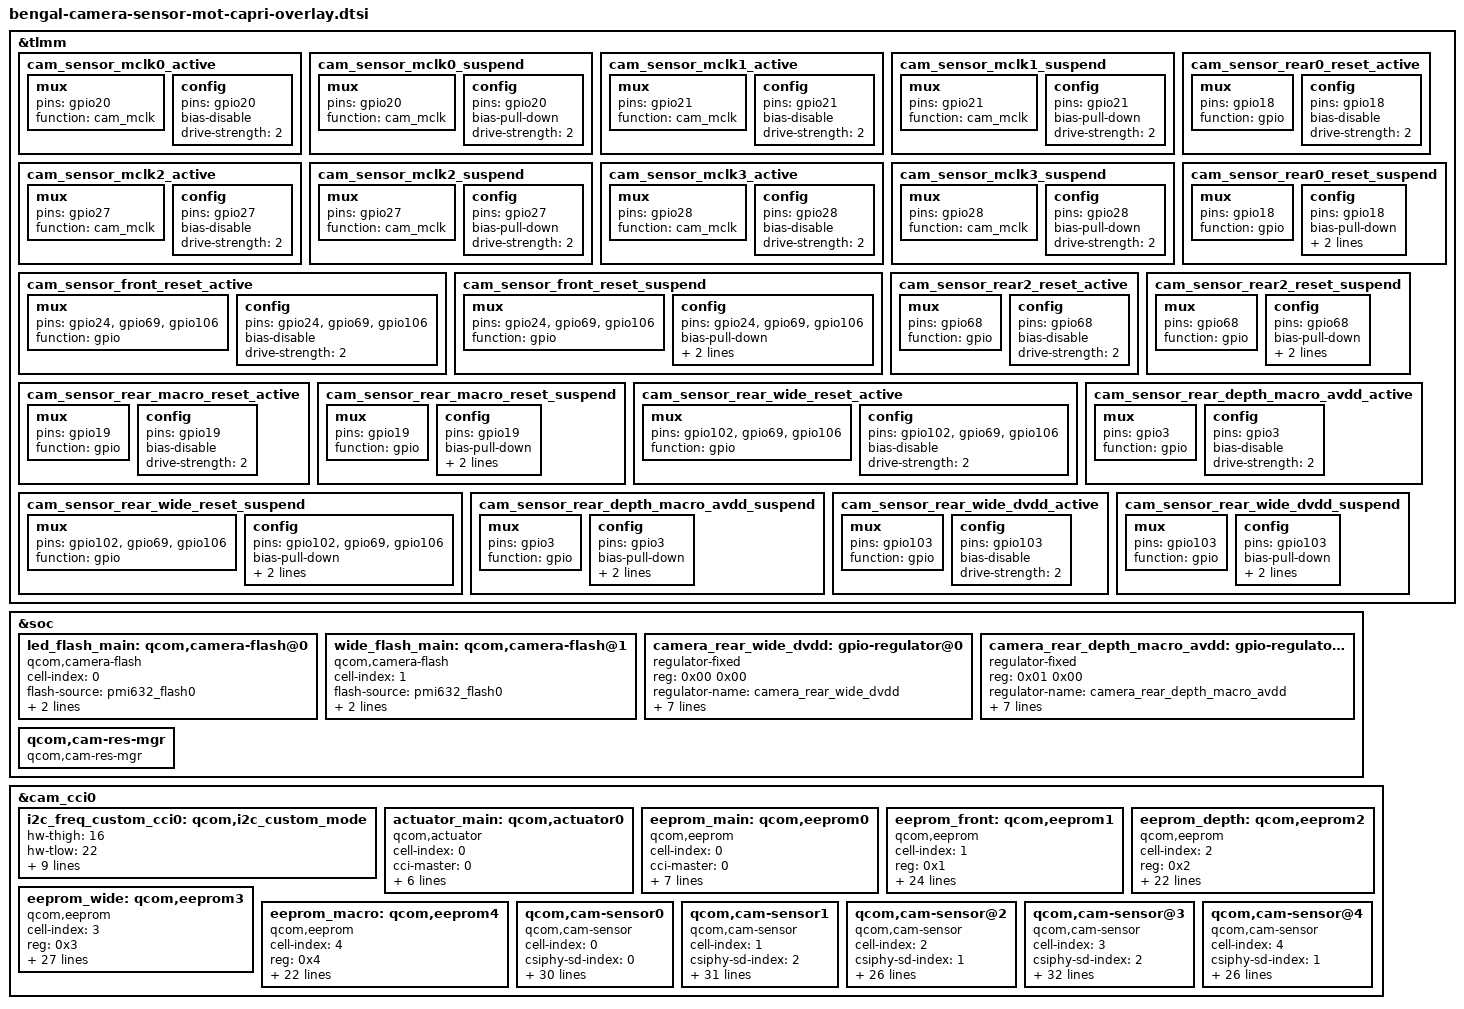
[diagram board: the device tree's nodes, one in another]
#include <dt-bindings/clock/qcom,gcc-bengal.h>


&tlmm {
	cam_sensor_mclk0_active: cam_sensor_mclk0_active {
		/* MCLK 0*/
		mux {
			pins = "gpio20";
			function = "cam_mclk";
		};

		config {
			pins = "gpio20";
			bias-disable;
			drive-strength = <2>;
		};
	};

	cam_sensor_mclk0_suspend: cam_sensor_mclk0_suspend {
		/* MCLK 0*/
		mux {
			pins = "gpio20";
			function = "cam_mclk";
		};

		config {
			pins = "gpio20";
			bias-pull-down;
			drive-strength = <2>;
		};
	};

	cam_sensor_mclk1_active: cam_sensor_mclk1_active {
		mux {
			pins = "gpio21";
			function = "cam_mclk";
		};

		config {
			pins = "gpio21";
			bias-disable; /* No PULL */
			drive-strength = <2>; /* 2 MA */
		};
	};

	cam_sensor_mclk1_suspend: cam_sensor_mclk1_suspend {
		mux {
			pins = "gpio21";
			function = "cam_mclk";
		};

		config {
			pins = "gpio21";
			bias-pull-down;
			drive-strength = <2>; /* 2 MA */
		};
	};

	cam_sensor_mclk2_active: cam_sensor_mclk2_active {
		mux {
			pins = "gpio27";
			function = "cam_mclk";
		};

		config {
			pins = "gpio27";
			bias-disable;
			drive-strength = <2>;
		};
	};

	cam_sensor_mclk2_suspend: cam_sensor_mclk2_suspend {
		mux {
			pins = "gpio27";
			function = "cam_mclk";
		};

		config {
			pins = "gpio27";
			bias-pull-down;
			drive-strength = <2>;
		};
	};

	cam_sensor_mclk3_active: cam_sensor_mclk3_active {
		/* MCLK 3*/
		mux {
			pins = "gpio28";
			function = "cam_mclk";
		};

		config {
			pins = "gpio28";
			bias-disable;
			drive-strength = <2>;
		};
	};

	cam_sensor_mclk3_suspend: cam_sensor_mclk3_suspend {
		/* MCLK 3*/
		mux {
			pins = "gpio28";
			function = "cam_mclk";
		};

		config {
			pins = "gpio28";
			bias-pull-down;
			drive-strength = <2>;
		};
	};

	cam_sensor_rear0_reset_active: cam_sensor_rear0_reset_active {
		mux {
			pins = "gpio18";
			function = "gpio";
		};

		config {
			pins = "gpio18";
			bias-disable; /* No PULL */
			drive-strength = <2>;
		};
	};

	cam_sensor_rear0_reset_suspend: cam_sensor_rear0_reset_suspend {
		mux {
			pins = "gpio18";
			function = "gpio";
		};

		config {
			pins = "gpio18";
			bias-pull-down; /* PULL DOWN */
			drive-strength = <2>;
			output-low;
		};
	};

	cam_sensor_front_reset_active: cam_sensor_front_reset_active {
		mux {
			pins = "gpio24", "gpio69", "gpio106";
			function = "gpio";
		};

		config {
			pins = "gpio24", "gpio69", "gpio106";
			bias-disable; /* No PULL */
			drive-strength = <2>;
		};
	};

	cam_sensor_front_reset_suspend: cam_sensor_front_reset_suspend {
		mux {
			pins = "gpio24", "gpio69", "gpio106";
			function = "gpio";
		};

		config {
			pins = "gpio24", "gpio69", "gpio106";
			bias-pull-down; /* PULL DOWN */
			drive-strength = <2>;
			output-low;
		};
	};

	cam_sensor_rear2_reset_active: cam_sensor_rear2_reset_active {
		mux {
			pins = "gpio68";
			function = "gpio";
		};

		config {
			pins = "gpio68";
			bias-disable; /* No PULL */
			drive-strength = <2>;
		};
	};

	cam_sensor_rear2_reset_suspend: cam_sensor_rear2_reset_suspend {
		mux {
			pins = "gpio68";
			function = "gpio";
		};

		config {
			pins = "gpio68";
			bias-pull-down; /* PULL DOWN */
			drive-strength = <2>;
			output-low;
		};
	};

	cam_sensor_rear_macro_reset_active: cam_sensor_rear_macro_reset_active {
		mux {
			pins = "gpio19";
			function = "gpio";
		};

		config {
			pins = "gpio19";
			bias-disable; /* No PULL */
			drive-strength = <2>; /* 2 MA */
		};
	};

	cam_sensor_rear_macro_reset_suspend: cam_sensor_rear_macro_reset_suspend {
		mux {
			pins = "gpio19";
			function = "gpio";
		};

		config {
			pins = "gpio19";
			bias-pull-down; /* PULL DOWN */
			drive-strength = <2>; /* 2 MA */
			output-low;
		};
	};

	cam_sensor_rear_wide_reset_active: cam_sensor_rear_wide_reset_active {
		mux {
			pins = "gpio102", "gpio69", "gpio106";
			function = "gpio";
		};

		config {
			pins = "gpio102", "gpio69", "gpio106";
			bias-disable; /* No PULL */
			drive-strength = <2>; /* 2 MA */
		};
	};

	cam_sensor_rear_wide_reset_suspend: cam_sensor_rear_wide_reset_suspend {
		mux {
			pins = "gpio102", "gpio69", "gpio106";
			function = "gpio";
		};

		config {
			pins = "gpio102", "gpio69", "gpio106";
			bias-pull-down; /* PULL DOWN */
			drive-strength = <2>; /* 2 MA */
			output-low;
		};
	};

	cam_sensor_rear_depth_macro_avdd_active: cam_sensor_rear_depth_macro_avdd_active {
		mux {
			pins = "gpio3";
			function = "gpio";
		};

		config {
			pins = "gpio3";
			bias-disable; /* No PULL */
			drive-strength = <2>; /* 2 MA */
		};
	};

	cam_sensor_rear_depth_macro_avdd_suspend: cam_sensor_rear_depth_macro_avdd_suspend {
		mux {
			pins = "gpio3";
			function = "gpio";
		};

		config {
			pins = "gpio3";
			bias-pull-down; /* PULL DOWN */
			drive-strength = <2>; /* 2 MA */
			output-low;
		};
	};

	cam_sensor_rear_wide_dvdd_active: cam_sensor_rear_wide_dvdd_active {
		mux {
			pins = "gpio103";
			function = "gpio";
		};

		config {
			pins = "gpio103";
			bias-disable; /* No PULL */
			drive-strength = <2>; /* 2 MA */
		};
	};

	cam_sensor_rear_wide_dvdd_suspend: cam_sensor_rear_wide_dvdd_suspend {
		mux {
			pins = "gpio103";
			function = "gpio";
		};

		config {
			pins = "gpio103";
			bias-pull-down; /* PULL DOWN */
			drive-strength = <2>; /* 2 MA */
			output-low;
		};
	};
};

&soc {
	led_flash_main: qcom,camera-flash@0 {
		cell-index = <0>;
		compatible = "qcom,camera-flash";
		flash-source  = <&pmi632_flash0>;
		torch-source  = <&pmi632_torch0>;
		switch-source = <&pmi632_switch0>;
		status = "ok";
	};

        wide_flash_main: qcom,camera-flash@1 {
		cell-index = <1>;
		compatible = "qcom,camera-flash";
		flash-source  = <&pmi632_flash0>;
		torch-source  = <&pmi632_torch0>;
		switch-source = <&pmi632_switch0>;
		status = "ok";
	};

	camera_rear_wide_dvdd: gpio-regulator@0 {
		compatible = "regulator-fixed";
		reg = <0x00 0x00>;
		regulator-name = "camera_rear_wide_dvdd";
		regulator-min-microvolt = <1200000>;
		regulator-max-microvolt = <1200000>;
		regulator-enable-ramp-delay = <233>;
		enable-active-high;
		gpio = <&tlmm 103 0>;
		pinctrl-names = "default";
		pinctrl-0 = <&cam_sensor_rear_wide_dvdd_active>;
		vin-supply = <&S6A>;
	};

	camera_rear_depth_macro_avdd: gpio-regulator@1 {
		compatible = "regulator-fixed";
		reg = <0x01 0x00>;
		regulator-name = "camera_rear_depth_macro_avdd";
		regulator-min-microvolt = <2800000>;
		regulator-max-microvolt = <2800000>;
		regulator-enable-ramp-delay = <233>;
		enable-active-high;
		gpio = <&tlmm 3 0>;
		pinctrl-names = "default";
		pinctrl-0 = <&cam_sensor_rear_depth_macro_avdd_active>;
	};

	qcom,cam-res-mgr {
		compatible = "qcom,cam-res-mgr";
		status = "ok";
	};
};

&cam_cci0 {
	i2c_freq_custom_cci0: qcom,i2c_custom_mode {
		hw-thigh = <16>;
		hw-tlow = <22>;
		hw-tsu-sto = <17>;
		hw-tsu-sta = <18>;
		hw-thd-dat = <16>;
		hw-thd-sta = <15>;
		hw-tbuf = <24>;
		hw-scl-stretch-en = <1>;
		hw-trdhld = <3>;
		hw-tsp = <3>;
		cci-clk-src = <37500000>;
		status = "ok";
	};

	actuator_main: qcom,actuator0 {
		cell-index = <0>;
		compatible = "qcom,actuator";
		cci-master = <0>;
		cam_vaf-supply = <&L5P>;
		regulator-names = "cam_vaf";
		rgltr-cntrl-support;
		rgltr-min-voltage = <2800000>;
		rgltr-max-voltage = <2800000>;
		rgltr-load-current = <100000>;
		status = "ok";
	};
	/*main : GM1*/
	eeprom_main: qcom,eeprom0 {
		cell-index = <0>;
		compatible = "qcom,eeprom";
		cci-master = <0>;
		cam_vaf-supply = <&L5P>;
		cam_vio-supply = <&L7P>;
		regulator-names = "cam_vaf", "cam_vio";
		rgltr-cntrl-support;
		rgltr-min-voltage = <2800000 1800000>;
		rgltr-max-voltage = <2800000 1800000>;
		rgltr-load-current = <100000 120000>;
		status = "ok";
	};
	/*front : 4h7*/
	eeprom_front: qcom,eeprom1 {
		cell-index = <1>;
		reg = <0x1>;
		compatible = "qcom,eeprom";
		cam_vio-supply = <&L7P>;
		cam_vana-supply = <&L6P>;
		cam_vdig-supply = <&L1P>;
		cam_clk-supply = <&gcc_camss_top_gdsc>;
		regulator-names = "cam_vio", "cam_vana", "cam_vdig",
			"cam_clk";
		rgltr-cntrl-support;
		rgltr-min-voltage = <1800000 2800000 1200000 0>;
		rgltr-max-voltage = <1800000 2800000 1200000 0>;
		rgltr-load-current = <120000 80000 1200000 0>;
		gpio-no-mux = <0>;
		pinctrl-names = "cam_default", "cam_suspend";
		pinctrl-0 = <&cam_sensor_mclk2_active
				&cam_sensor_front_reset_active>;
		pinctrl-1 = <&cam_sensor_mclk2_suspend
				&cam_sensor_front_reset_suspend>;
		gpios = <&tlmm 27 0>,
			<&tlmm 24 0>;
		gpio-reset = <1>;
		gpio-req-tbl-num = <0 1>;
		gpio-req-tbl-flags = <1 0>;
		gpio-req-tbl-label = "CAMIF_MCLK2",
					"CAM_RESET2";
		cci-master = <1>;
		status = "ok";
		clocks = <&gcc GCC_CAMSS_MCLK2_CLK>;
		clock-names = "cam_clk";
		clock-cntl-level = "turbo";
		clock-rates = <24000000>;
	};
	/*depth : ov02b1b*/
	eeprom_depth: qcom,eeprom2 {
		cell-index = <2>;
		reg = <0x2>;
		compatible = "qcom,eeprom";
		cam_vio-supply = <&L7P>;
		cam_vana-supply = <&camera_rear_depth_macro_avdd>;
		cam_clk-supply = <&gcc_camss_top_gdsc>;
		regulator-names = "cam_vio", "cam_vana", "cam_clk";
		rgltr-cntrl-support;
		rgltr-min-voltage = <1800000 2800000 0>;
		rgltr-max-voltage = <1800000 2800000 0>;
		rgltr-load-current = <120000 80000 0>;
		gpio-no-mux = <0>;
		pinctrl-names = "cam_default", "cam_suspend";
		pinctrl-0 = <&cam_sensor_mclk3_active
				&cam_sensor_rear2_reset_active>;
		pinctrl-1 = <&cam_sensor_mclk3_suspend
				&cam_sensor_rear2_reset_suspend>;
		gpios = <&tlmm 28 0>,
			<&tlmm 68 0>;
		gpio-reset = <1>;
		gpio-req-tbl-num = <0 1>;
		gpio-req-tbl-flags = <1 0>;
		gpio-req-tbl-label = "CAMIF_MCLK3",
					"CAM_PWDN";
		cci-master = <1>;
		status = "ok";
		clocks = <&gcc GCC_CAMSS_MCLK3_CLK>;
		clock-names = "cam_clk";
		clock-cntl-level = "turbo";
		clock-rates = <24000000>;
	};
	/*wide : 4h7*/
	eeprom_wide: qcom,eeprom3 {
		cell-index = <3>;
		reg = <0x3>;
		compatible = "qcom,eeprom";
		cam_vio-supply = <&L7P>;
		cam_vana-supply = <&L3P>;
		cam_vdig-supply = <&camera_rear_wide_dvdd>;
		cam_clk-supply = <&gcc_camss_top_gdsc>;
		regulator-names = "cam_vio", "cam_vana", "cam_vdig",
			"cam_clk";
		rgltr-cntrl-support;
		rgltr-min-voltage = <1800000 2800000 1200000 0>;
		rgltr-max-voltage = <1800000 2800000 1200000 0>;
		rgltr-load-current = <120000 80000 1200000 0>;
		gpio-no-mux = <0>;
		pinctrl-names = "cam_default", "cam_suspend";
		pinctrl-0 = <&cam_sensor_mclk2_active
				&cam_sensor_rear_wide_reset_active>;
		pinctrl-1 = <&cam_sensor_mclk2_suspend
				&cam_sensor_rear_wide_reset_suspend>;
		gpios = <&tlmm 27 0>,
			<&tlmm 102 0>,
			<&tlmm 69 0>,
			<&tlmm 106 0>;
		gpio-reset = <1>;
		gpio-custom1 = <2>;
		gpio-custom2 = <3>;//sel:low for front high for wide
		gpio-req-tbl-num = <0 1 2 3>;
		gpio-req-tbl-flags = <1 0 0 0>;
		gpio-req-tbl-label = "CAMIF_MCLK2",
					"CAM_RESET2",
					"CAM_MIPI_OE",
					"CAM_MIPI_SEL";
		cci-master = <1>;
		status = "ok";
		clocks = <&gcc GCC_CAMSS_MCLK2_CLK>;
		clock-names = "cam_clk";
		clock-cntl-level = "turbo";
		clock-rates = <24000000>;
	};

	/* macro : ov02b10 */
	eeprom_macro: qcom,eeprom4 {
		cell-index = <4>;
		reg = <0x4>;
		compatible = "qcom,eeprom";
		cam_vio-supply = <&L7P>;
		cam_vana-supply = <&camera_rear_depth_macro_avdd>;
		cam_clk-supply = <&gcc_camss_top_gdsc>;
		regulator-names = "cam_vio", "cam_vana", "cam_clk";
		rgltr-cntrl-support;
		rgltr-min-voltage = <1800000 2800000 0>;
		rgltr-max-voltage = <1800000 2800000 0>;
		rgltr-load-current = <120000 80000 0>;
		gpio-no-mux = <0>;
		pinctrl-names = "cam_default", "cam_suspend";
		pinctrl-0 = <&cam_sensor_mclk1_active
				&cam_sensor_rear_macro_reset_active>;
		pinctrl-1 = <&cam_sensor_mclk1_suspend
				&cam_sensor_rear_macro_reset_suspend>;
		gpios = <&tlmm 21 0>,
			<&tlmm 19 0>;
		gpio-reset = <1>;
		gpio-req-tbl-num = <0 1>;
		gpio-req-tbl-flags = <1 0>;
		gpio-req-tbl-label = "CAMIF_MCLK1",
					"CAM_PWDN";
		cci-master = <0>;
		status = "ok";
		clocks = <&gcc GCC_CAMSS_MCLK1_CLK>;
		clock-names = "cam_clk";
		clock-cntl-level = "turbo";
		clock-rates = <24000000>;
	};

	 /* main : GM1*/
	qcom,cam-sensor0 {
		cell-index = <0>;
		compatible = "qcom,cam-sensor";
		csiphy-sd-index = <0>;
		sensor-position-roll = <90>;
		sensor-position-pitch = <0>;
		sensor-position-yaw = <180>;
		actuator-src = <&actuator_main>;
		led-flash-src = <&led_flash_main>;
		eeprom-src = <&eeprom_main>;
		cam_vio-supply = <&L7P>;
		cam_vana-supply = <&L4P>;
		cam_vdig-supply = <&L2P>;
		cam_clk-supply = <&gcc_camss_top_gdsc>;
		regulator-names = "cam_vio", "cam_vana", "cam_vdig",
			"cam_clk";
		rgltr-cntrl-support;
		rgltr-min-voltage = <1800000 2800000 1050000 0>;
		rgltr-max-voltage = <1800000 2800000 1050000 0>;
		rgltr-load-current = <120000 80000 1200000 0>;
		gpio-no-mux = <0>;
		pinctrl-names = "cam_default", "cam_suspend";
		pinctrl-0 = <&cam_sensor_mclk0_active
				&cam_sensor_rear0_reset_active>;
		pinctrl-1 = <&cam_sensor_mclk0_suspend
				&cam_sensor_rear0_reset_suspend>;
		gpios = <&tlmm 20 0>,
			<&tlmm 18 0>;
		gpio-reset = <1>;
		gpio-req-tbl-num = <0 1>;
		gpio-req-tbl-flags = <1 0>;
		gpio-req-tbl-label = "CAMIF_MCLK0",
					"CAM_RESET0";
		cci-master = <0>;
		status = "ok";
		clocks = <&gcc GCC_CAMSS_MCLK0_CLK>;
		clock-names = "cam_clk";
		clock-cntl-level = "turbo";
		clock-rates = <24000000>;
	};

	 /* front : 4h7*/
	qcom,cam-sensor1 {
		cell-index = <1>;
		compatible = "qcom,cam-sensor";
		csiphy-sd-index = <2>;
		sensor-position-roll = <270>;
		sensor-position-pitch = <0>;
		sensor-position-yaw = <0>;
		eeprom-src = <&eeprom_front>;
		cam_vio-supply = <&L7P>;
		cam_vana-supply = <&L6P>;
		cam_vdig-supply = <&L1P>;
		cam_clk-supply = <&gcc_camss_top_gdsc>;
		regulator-names = "cam_vio", "cam_vana", "cam_vdig",
			"cam_clk";
		rgltr-cntrl-support;
		rgltr-min-voltage = <1800000 2800000 1200000 0>;
		rgltr-max-voltage = <1800000 2800000 1200000 0>;
		rgltr-load-current = <120000 80000 1200000 0>;
		gpio-no-mux = <0>;
		pinctrl-names = "cam_default", "cam_suspend";
		pinctrl-0 = <&cam_sensor_mclk2_active
				&cam_sensor_front_reset_active>;
		pinctrl-1 = <&cam_sensor_mclk2_suspend
				&cam_sensor_front_reset_suspend>;
		gpios = <&tlmm 27 0>,
			<&tlmm 24 0>,
			<&tlmm 69 0>,
			<&tlmm 106 0>;
		gpio-reset = <1>;
		gpio-custom1 = <2>;
		gpio-custom2 = <3>;/*sel:low for front high for wide */
		gpio-req-tbl-num = <0 1 2 3>;
		gpio-req-tbl-flags = <1 0 0 0>;
		gpio-req-tbl-label = "CAMIF_MCLK2",
					"CAM_RESET2",
					"CAM_MIPI_OE",
					"CAM_MIPI_SEL";
		cci-master = <1>;
		status = "ok";
		clocks = <&gcc GCC_CAMSS_MCLK2_CLK>;
		clock-names = "cam_clk";
		clock-cntl-level = "turbo";
		clock-rates = <24000000>;
	};

	 /* depth : ov02b1b */
	qcom,cam-sensor@2 {
		cell-index = <2>;
		compatible = "qcom,cam-sensor";
		csiphy-sd-index = <1>;
		sensor-position-roll = <90>;
		sensor-position-pitch = <0>;
		sensor-position-yaw = <180>;
		eeprom-src = <&eeprom_depth>;
		cam_vio-supply = <&L7P>;
		cam_vana-supply = <&camera_rear_depth_macro_avdd>;
		cam_clk-supply = <&gcc_camss_top_gdsc>;
		regulator-names = "cam_vio", "cam_vana", "cam_clk";
		rgltr-cntrl-support;
		rgltr-min-voltage = <1800000 2800000 0>;
		rgltr-max-voltage = <1800000 2800000 0>;
		rgltr-load-current = <120000 80000 0>;
		gpio-no-mux = <0>;
		pinctrl-names = "cam_default", "cam_suspend";
		pinctrl-0 = <&cam_sensor_mclk3_active
				&cam_sensor_rear2_reset_active>;
		pinctrl-1 = <&cam_sensor_mclk3_suspend
				&cam_sensor_rear2_reset_suspend>;
		gpios = <&tlmm 28 0>,
			<&tlmm 68 0>;
		gpio-reset = <1>;
		gpio-req-tbl-num = <0 1>;
		gpio-req-tbl-flags = <1 0>;
		gpio-req-tbl-label = "CAMIF_MCLK3",
					"CAM_PWDN";
		cci-master = <1>;
		status = "ok";
		clocks = <&gcc GCC_CAMSS_MCLK3_CLK>;
		clock-names = "cam_clk";
		clock-cntl-level = "turbo";
		clock-rates = <24000000>;
	};

	 /* wide : 4h7 */
	qcom,cam-sensor@3 {
		cell-index = <3>;
		compatible = "qcom,cam-sensor";
		csiphy-sd-index = <2>;
		sensor-position-roll = <90>;
		sensor-position-pitch = <0>;
		sensor-position-yaw = <180>;
		eeprom-src = <&eeprom_wide>;
		led-flash-src = <&wide_flash_main>;
		cam_vio-supply = <&L7P>;
		cam_vana-supply = <&L3P>;
		cam_vdig-supply = <&camera_rear_wide_dvdd>;
		cam_clk-supply = <&gcc_camss_top_gdsc>;
		regulator-names = "cam_vio", "cam_vana", "cam_vdig",
			"cam_clk";
		rgltr-cntrl-support;
		rgltr-min-voltage = <1800000 2800000 1200000 0>;
		rgltr-max-voltage = <1800000 2800000 1200000 0>;
		rgltr-load-current = <120000 80000 1200000 0>;
		gpio-no-mux = <0>;
		pinctrl-names = "cam_default", "cam_suspend";
		pinctrl-0 = <&cam_sensor_mclk2_active
				&cam_sensor_rear_wide_reset_active>;
		pinctrl-1 = <&cam_sensor_mclk2_suspend
				&cam_sensor_rear_wide_reset_suspend>;
		gpios = <&tlmm 27 0>,
			<&tlmm 102 0>,
			<&tlmm 69 0>,
			<&tlmm 106 0>;
		gpio-reset = <1>;
		gpio-custom1 = <2>;
		gpio-custom2 = <3>;//sel:low for front high for wide
		gpio-req-tbl-num = <0 1 2 3>;
		gpio-req-tbl-flags = <1 0 0 0>;
		gpio-req-tbl-label = "CAMIF_MCLK2",
					"CAM_RESET2",
					"CAM_MIPI_OE",
					"CAM_MIPI_SEL";
		cci-master = <1>;
		status = "ok";
		clocks = <&gcc GCC_CAMSS_MCLK2_CLK>;
		clock-names = "cam_clk";
		clock-cntl-level = "turbo";
		clock-rates = <24000000>;
	};

	 /* macro : ov02b10 */
	qcom,cam-sensor@4 {
		cell-index = <4>;
		compatible = "qcom,cam-sensor";
		csiphy-sd-index = <1>;
		sensor-position-roll = <90>;
		sensor-position-pitch = <0>;
		sensor-position-yaw = <180>;
		//eeprom-src = <&eeprom_macro>;
		led-flash-src = <&led_flash_main>;
		cam_vio-supply = <&L7P>;
		cam_vana-supply = <&camera_rear_depth_macro_avdd>;
		cam_clk-supply = <&gcc_camss_top_gdsc>;
		regulator-names = "cam_vio", "cam_vana", "cam_clk";
		rgltr-cntrl-support;
		rgltr-min-voltage = <1800000 2800000 0>;
		rgltr-max-voltage = <1800000 2800000 0>;
		rgltr-load-current = <120000 80000 0>;
		gpio-no-mux = <0>;
		pinctrl-names = "cam_default", "cam_suspend";
		pinctrl-0 = <&cam_sensor_mclk1_active
				&cam_sensor_rear_macro_reset_active>;
		pinctrl-1 = <&cam_sensor_mclk1_suspend
				&cam_sensor_rear_macro_reset_suspend>;
		gpios = <&tlmm 21 0>,
			<&tlmm 19 0>;
		gpio-reset = <1>;
		gpio-req-tbl-num = <0 1>;
		gpio-req-tbl-flags = <1 0>;
		gpio-req-tbl-label = "CAMIF_MCLK1",
					"CAM_PWDN";
		cci-master = <0>;
		status = "ok";
		clocks = <&gcc GCC_CAMSS_MCLK1_CLK>;
		clock-names = "cam_clk";
		clock-cntl-level = "turbo";
		clock-rates = <24000000>;
	};

};
